# C7X256V_DEBUG_C7X256V_DEBUG_DBG_AGR0_MMR_000734040000h register map
Vendor: Texas Instruments
Peripheral module from a debugger description file (folder am62D).
Registers are 32-bit, access per field, reset values left out (the file's numbers can be read two ways) unless marked. A register's access mark holds for its fields unless they carry their own. Offsets are as the file gives them; lines under a group give offsets from that group; [hi:lo] are bit positions; {n}, {i} and the like mark numbered series; 'fields as' and 'values as' point back to an identical list; <NAME> marks a mode.

## C7X256V_DEBUG_DBG_AGR0_MMR
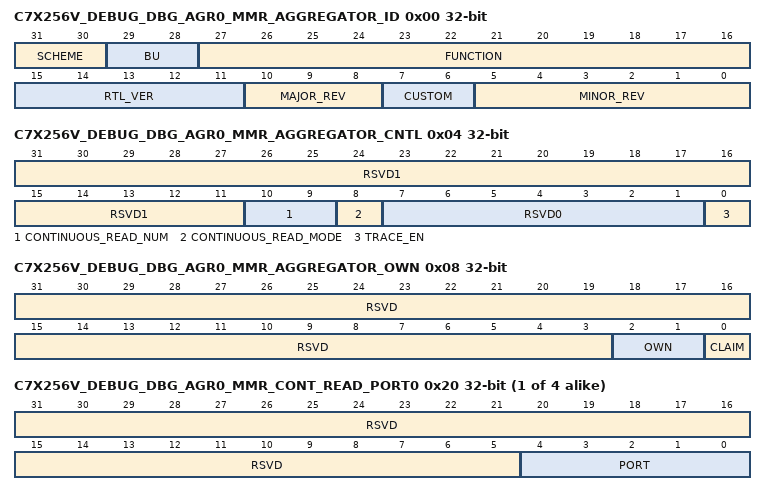
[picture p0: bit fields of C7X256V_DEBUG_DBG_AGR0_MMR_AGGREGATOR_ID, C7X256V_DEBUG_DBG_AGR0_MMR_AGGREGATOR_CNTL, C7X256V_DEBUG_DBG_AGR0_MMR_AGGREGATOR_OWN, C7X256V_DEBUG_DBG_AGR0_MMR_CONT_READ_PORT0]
0x00 C7X256V_DEBUG_DBG_AGR0_MMR_AGGREGATOR_ID ro — This is the standard TI peripheral ID register that exists at address 0 in the preipheral space
  [31:30] SCHEME — Reset Source: cfg_rst_n
  [29:28] BU — Reset Source: cfg_rst_n
  [27:16] FUNCTION — Reset Source: cfg_rst_n
  [15:11] RTL_VER — Reset Source: cfg_rst_n
  [10:8] MAJOR_REV — Reset Source: cfg_rst_n
  [7:6] CUSTOM — Reset Source: cfg_rst_n
  [5:0] MINOR_REV — Reset Source: cfg_rst_n
0x04 C7X256V_DEBUG_DBG_AGR0_MMR_AGGREGATOR_CNTL — This register contains the controls for serial indrect access and trace processing
  [31:11] RSVD1 ro — Reset Source: cfg_rst_n
  [10:9] CONTINUOUS_READ_NUM rw — Reset Source: cfg_rst_n
  [8] CONTINUOUS_READ_MODE rw — Reset Source: cfg_rst_n
  [7:1] RSVD0 ro — Reset Source: cfg_rst_n
  [0] TRACE_EN rw — Reset Source: cfg_rst_n
0x08 C7X256V_DEBUG_DBG_AGR0_MMR_AGGREGATOR_OWN — Module Ownership Control and Status Register
  [31:3] RSVD ro — Reset Source: cfg_rst_n
  [2:1] OWN ro — Reset Source: cfg_rst_n
  [0] CLAIM rw — Reset Source: cfg_rst_n
{0x20+0x10*i} C7X256V_DEBUG_DBG_AGR0_MMR_CONT_READ_PORT{i} (i=0..3) — Designates which port (peripheral) is the target of this port, address, data register group
  [31:5] RSVD ro — Reset Source: cfg_rst_n
  [4:0] PORT rw — Reset Source: cfg_rst_n
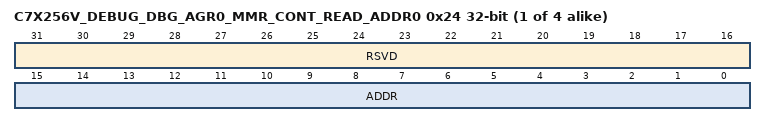
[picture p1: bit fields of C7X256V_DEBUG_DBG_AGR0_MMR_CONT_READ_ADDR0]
{0x24+0x10*i} C7X256V_DEBUG_DBG_AGR0_MMR_CONT_READ_ADDR{i} (i=0..3) — Designates the offest (in peripheral space) that is the target of this port, address, data register group
  [31:16] RSVD ro — Reset Source: cfg_rst_n
  [15:0] ADDR rw — Reset Source: cfg_rst_n
{0x28+0x10*i} C7X256V_DEBUG_DBG_AGR0_MMR_CONT_READ_DATA{i} ro (i=0..3) — Provides the continuous read data for this port, address, data register group
  [31:0] DATA — Reset Source: cfg_rst_n
